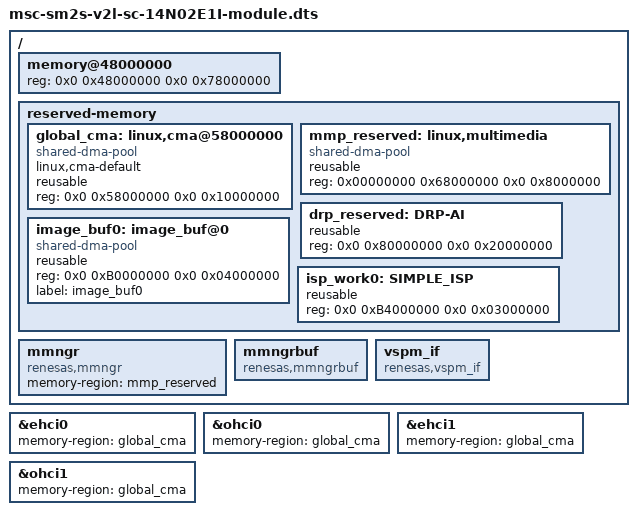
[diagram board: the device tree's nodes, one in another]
/*                                                                    
 * Copyright (C) 2023 Avnet Embedded GmbH                             
 *                                                                    
 * This program is free software; you can redistribute it and/or      
 * modify it under the terms of the GNU General Public License as     
 * published by the Free Software Foundation version 2.               
 *                                                                    
 * This program is distributed "as is" WITHOUT ANY WARRANTY of any    
 * kind, whether express or implied; without even the implied warranty
 * of MERCHANTABILITY or FITNESS FOR A PARTICULAR PURPOSE.  See the   
 * GNU General Public License for more details.                       
 */                                                                   

/dts-v1/;
#include "../../renesas/r9a07g054.dtsi"
#include "msc-sm2s-rzv2l-dv1-module.dtsi"

/ {
	memory@48000000 {
		device_type = "memory";
		/* first 128MB is reserved for secure area. */
		reg = <0x0 0x48000000 0x0 0x78000000>;
	};

	reserved-memory {
		#address-cells = <2>;
		#size-cells = <2>;
		ranges;

		global_cma: linux,cma@58000000 {
			compatible = "shared-dma-pool";
			linux,cma-default;
			reusable;
			reg = <0x0 0x58000000 0x0 0x10000000>;
		};
		mmp_reserved: linux,multimedia {
		        compatible = "shared-dma-pool";
		        reusable;
		        reg = <0x00000000 0x68000000 0x0 0x8000000>;
		};

		/* device specific region for contiguous allocations */
		drp_reserved: DRP-AI {
			reusable;
			reg = <0x0 0x80000000 0x0 0x20000000>;
		};

		image_buf0: image_buf@0 {
			compatible = "shared-dma-pool";
			reusable;
			reg = <0x0 0xB0000000 0x0 0x04000000>;
			label = "image_buf0";
		};

		isp_work0: SIMPLE_ISP {
			reusable;
			reg = <0x0 0xB4000000 0x0 0x03000000>;
		};
	};

        mmngr {
                compatible = "renesas,mmngr";
                memory-region = <&mmp_reserved>;
        };

        mmngrbuf {
                compatible = "renesas,mmngrbuf";
        };

        vspm_if {
                compatible = "renesas,vspm_if";
        };
};

&ehci0 {
        memory-region = <&global_cma>;
};

&ohci0 {
        memory-region = <&global_cma>;
};

&ehci1 {
        memory-region = <&global_cma>;
};

&ohci1 {
        memory-region = <&global_cma>;
};
